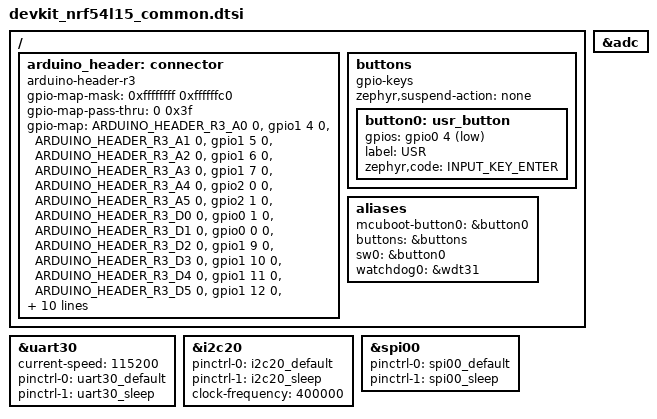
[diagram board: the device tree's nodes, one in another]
/*
 * SPDX-FileCopyrightText: FoBE Studio
 * SPDX-License-Identifier: Apache-2.0
 */

#include <zephyr/dt-bindings/gpio/arduino-header-r3.h>
#include <zephyr/dt-bindings/input/input-event-codes.h>
#include "devkit_nrf54l15-pinctrl.dtsi"

/ {
	arduino_header: connector {
		compatible = "arduino-header-r3";
		#gpio-cells = <2>;
		gpio-map-mask = <0xffffffff 0xffffffc0>;
		gpio-map-pass-thru = <0 0x3f>;
		gpio-map = <ARDUINO_HEADER_R3_A0 0 &gpio1 4 0>,
			   <ARDUINO_HEADER_R3_A1 0 &gpio1 5 0>,
			   <ARDUINO_HEADER_R3_A2 0 &gpio1 6 0>,
			   <ARDUINO_HEADER_R3_A3 0 &gpio1 7 0>,
			   <ARDUINO_HEADER_R3_A4 0 &gpio2 0 0>,
			   <ARDUINO_HEADER_R3_A5 0 &gpio2 1 0>,
			   <ARDUINO_HEADER_R3_D0 0 &gpio0 1 0>,
			   <ARDUINO_HEADER_R3_D1 0 &gpio0 0 0>,
			   <ARDUINO_HEADER_R3_D2 0 &gpio1 9 0>,
			   <ARDUINO_HEADER_R3_D3 0 &gpio1 10 0>,
			   <ARDUINO_HEADER_R3_D4 0 &gpio1 11 0>,
			   <ARDUINO_HEADER_R3_D5 0 &gpio1 12 0>,
			   <ARDUINO_HEADER_R3_D6 0 &gpio1 13 0>,
			   <ARDUINO_HEADER_R3_D7 0 &gpio1 14 0>,
			   <ARDUINO_HEADER_R3_D8 0 &gpio1 8 0>,
			   <ARDUINO_HEADER_R3_D9 0 &gpio2 10 0>,
			   <ARDUINO_HEADER_R3_D10 0 &gpio2 7 0>,
			   <ARDUINO_HEADER_R3_D11 0 &gpio2 8 0>,
			   <ARDUINO_HEADER_R3_D12 0 &gpio2 9 0>,
			   <ARDUINO_HEADER_R3_D13 0 &gpio2 6 0>,
			   <ARDUINO_HEADER_R3_D14 0 &gpio1 2 0>,
			   <ARDUINO_HEADER_R3_D15 0 &gpio1 3 0>;
	};

	buttons: buttons {
		compatible = "gpio-keys";
		zephyr,suspend-action = "none";

		button0: usr_button {
			gpios = <&gpio0 4 (GPIO_PULL_UP | GPIO_ACTIVE_LOW)>;
			label = "USR";
			zephyr,code = <INPUT_KEY_ENTER>;
		};
	};

	aliases {
		mcuboot-button0 = &button0;
		buttons = &buttons;
		sw0 = &button0;
		watchdog0 = &wdt31;
	};
};

&uart30 {
	current-speed = <115200>;
	pinctrl-0 = <&uart30_default>;
	pinctrl-1 = <&uart30_sleep>;
	pinctrl-names = "default", "sleep";
};

&i2c20 {
	pinctrl-0 = <&i2c20_default>;
	pinctrl-1 = <&i2c20_sleep>;
	pinctrl-names = "default", "sleep";
	clock-frequency = <400000>;
};

&spi00 {
	pinctrl-0 = <&spi00_default>;
	pinctrl-1 = <&spi00_sleep>;
	pinctrl-names = "default", "sleep";
};

&adc {
	#address-cells = <1>;
	#size-cells = <0>;
};

arduino_serial: &uart30 {};

arduino_i2c: &i2c20 {};

arduino_spi: &spi00 {};
